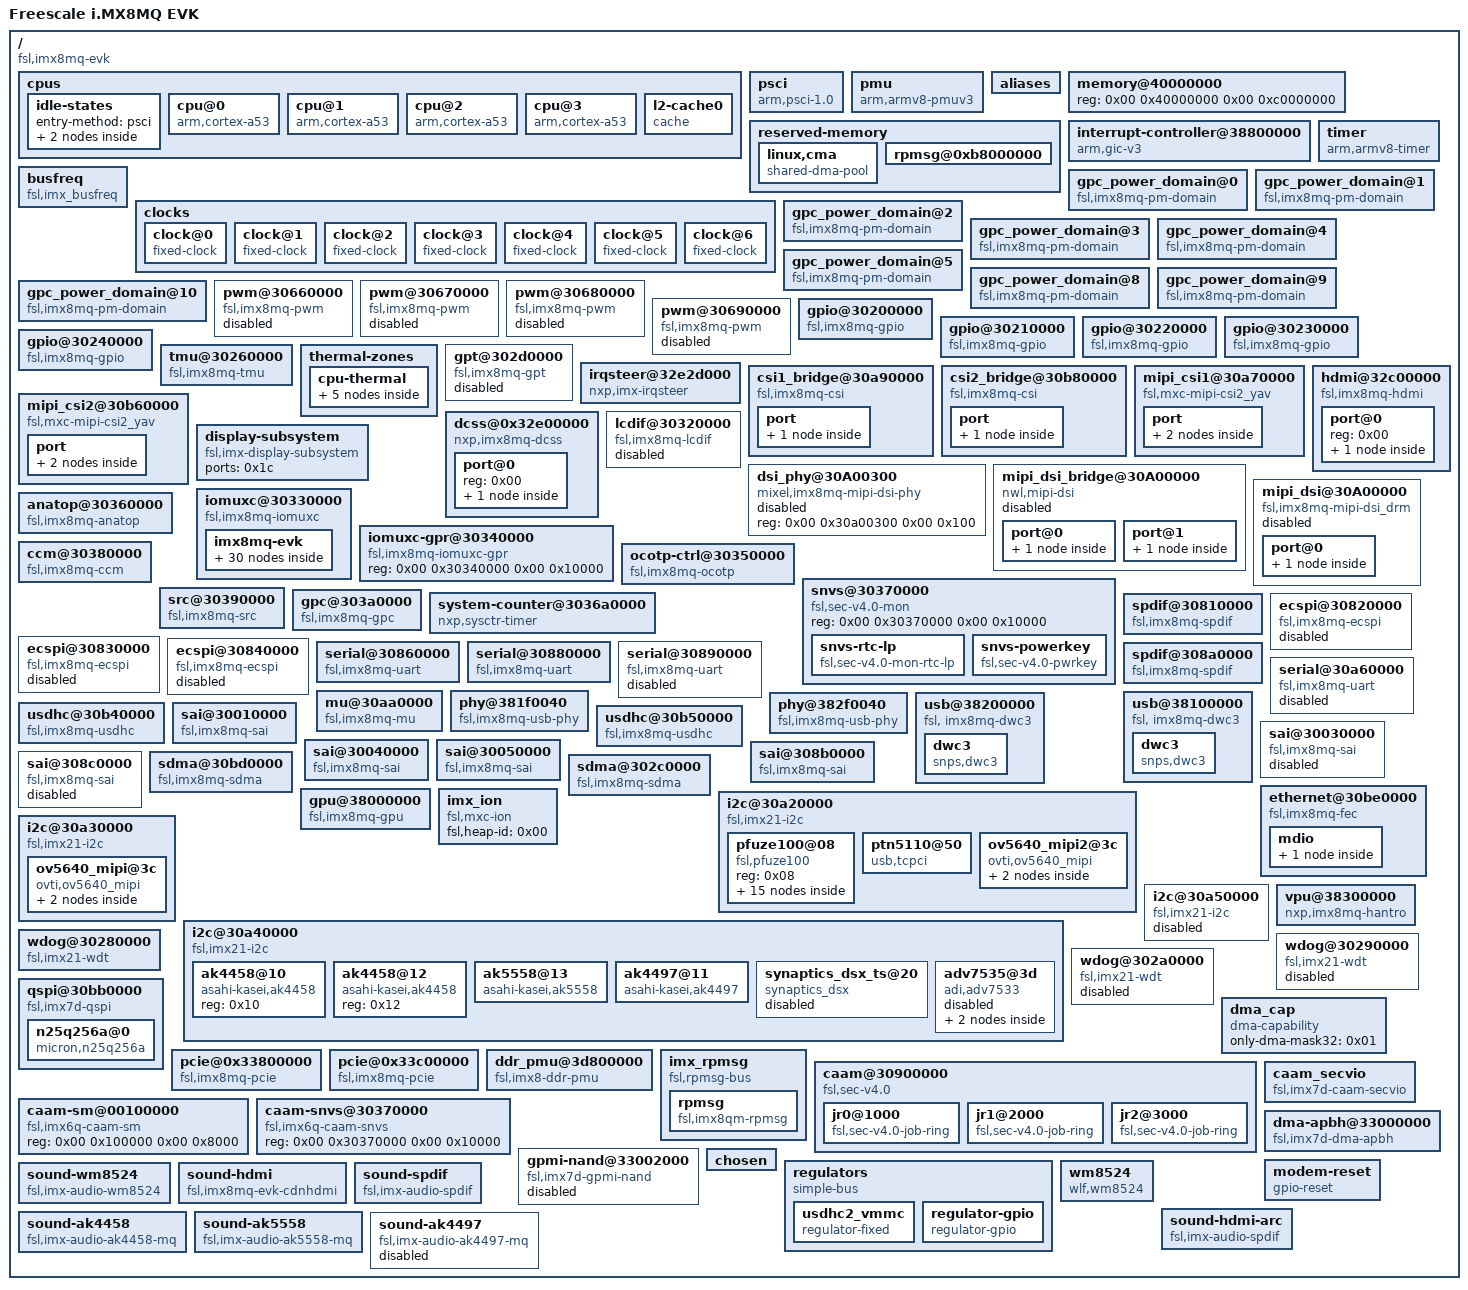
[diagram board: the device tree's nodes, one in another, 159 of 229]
/*
 * Copyright Linux Kernel Team
 *
 * SPDX-License-Identifier: GPL-2.0-only
 *
 * This file is derived from an intermediate build stage of the
 * Linux kernel. The licenses of all input files to this process
 * are compatible with GPL-2.0-only.
 */

/dts-v1/;

/ {
	compatible = "fsl,imx8mq-evk\0fsl,imx8mq";
	interrupt-parent = < 0x01 >;
	#address-cells = < 0x02 >;
	#size-cells = < 0x02 >;
	model = "Freescale i.MX8MQ EVK";

	cpus {
		#address-cells = < 0x02 >;
		#size-cells = < 0x00 >;

		idle-states {
			entry-method = "psci";

			cpu-sleep {
				compatible = "arm,idle-state";
				arm,psci-suspend-param = < 0x10033 >;
				entry-latency-us = < 0x3e8 >;
				exit-latency-us = < 0x2bc >;
				min-residency-us = < 0xa8c >;
				local-timer-stop;
				wakeup-latency-us = < 0x5dc >;
				linux,phandle = < 0x03 >;
				phandle = < 0x03 >;
			};

			cluster-sleep {
				compatible = "arm,idle-state";
				arm,psci-suspend-param = < 0x1000000 >;
				entry-latency-us = < 0x3e8 >;
				exit-latency-us = < 0x2bc >;
				min-residency-us = < 0xa8c >;
				wakeup-latency-us = < 0x5dc >;
			};
		};

		cpu@0 {
			device_type = "cpu";
			compatible = "arm,cortex-a53";
			reg = < 0x00 0x00 >;
			enable-method = "psci";
			next-level-cache = < 0x02 >;
			cpu-idle-states = < 0x03 >;
			operating-points = < 0x16e360 0xf4240 0x13d620 0xf4240 0xf4240 0xdbba0 0xc3500 0xdbba0 >;
			clocks = < 0x04 0x5a 0x04 0x58 0x04 0x0a 0x04 0x0c 0x04 0x4e >;
			clock-names = "a53\0arm_a53_src\0arm_pll\0arm_pll_out\0sys1_pll_800m";
			clock-latency = < 0xee6c >;
			#cooling-cells = < 0x02 >;
			dc-supply = < 0x05 >;
			linux,phandle = < 0x06 >;
			phandle = < 0x06 >;
		};

		cpu@1 {
			device_type = "cpu";
			compatible = "arm,cortex-a53";
			reg = < 0x00 0x01 >;
			enable-method = "psci";
			next-level-cache = < 0x02 >;
			cpu-idle-states = < 0x03 >;
			linux,phandle = < 0x07 >;
			phandle = < 0x07 >;
		};

		cpu@2 {
			device_type = "cpu";
			compatible = "arm,cortex-a53";
			reg = < 0x00 0x02 >;
			enable-method = "psci";
			next-level-cache = < 0x02 >;
			cpu-idle-states = < 0x03 >;
			linux,phandle = < 0x08 >;
			phandle = < 0x08 >;
		};

		cpu@3 {
			device_type = "cpu";
			compatible = "arm,cortex-a53";
			reg = < 0x00 0x03 >;
			enable-method = "psci";
			next-level-cache = < 0x02 >;
			cpu-idle-states = < 0x03 >;
			linux,phandle = < 0x09 >;
			phandle = < 0x09 >;
		};

		l2-cache0 {
			compatible = "cache";
			linux,phandle = < 0x02 >;
			phandle = < 0x02 >;
		};
	};

	psci {
		compatible = "arm,psci-1.0";
		method = "smc";
		cpu_suspend = < 0xc4000001 >;
		cpu_off = < 0xc4000002 >;
		cpu_on = < 0xc4000003 >;
	};

	pmu {
		compatible = "arm,armv8-pmuv3";
		interrupts = < 0x01 0x07 0x3f04 >;
		interrupt-affinity = < 0x06 0x07 0x08 0x09 >;
		interrupt-parent = < 0x0a >;
	};

	aliases {
		csi0 = "/mipi_csi1@30a70000";
		csi1 = "/mipi_csi2@30b60000";
		ethernet0 = "/ethernet@30be0000";
		serial0 = "/serial@30860000";
		serial1 = "/serial@30890000";
		serial2 = "/serial@30880000";
		serial3 = "/serial@30a60000";
		spi0 = "/ecspi@30820000";
		spi1 = "/ecspi@30830000";
		spi2 = "/ecspi@30840000";
		mmc0 = "/usdhc@30b40000";
		mmc1 = "/usdhc@30b50000";
		gpio0 = "/gpio@30200000";
		gpio1 = "/gpio@30210000";
		gpio2 = "/gpio@30220000";
		gpio3 = "/gpio@30230000";
		gpio4 = "/gpio@30240000";
		dsi_phy0 = "/dsi_phy@30A00300";
		mipi_dsi0 = "/mipi_dsi@30A00000";
	};

	memory@40000000 {
		device_type = "memory";
		reg = < 0x00 0x40000000 0x00 0xc0000000 >;
	};

	reserved-memory {
		#address-cells = < 0x02 >;
		#size-cells = < 0x02 >;
		ranges;

		linux,cma {
			compatible = "shared-dma-pool";
			reusable;
			size = < 0x00 0x3c000000 >;
			alloc-ranges = < 0x00 0x40000000 0x00 0x40000000 >;
			linux,cma-default;
		};

		rpmsg@0xb8000000 {
			no-map;
			reg = < 0x00 0xb8000000 0x00 0x400000 >;
			linux,phandle = < 0x58 >;
			phandle = < 0x58 >;
		};
	};

	interrupt-controller@38800000 {
		compatible = "arm,gic-v3";
		reg = < 0x00 0x38800000 0x00 0x10000 0x00 0x38880000 0x00 0xc0000 0x00 0x30340000 0x00 0x10000 >;
		#interrupt-cells = < 0x03 >;
		interrupt-controller;
		interrupts = < 0x01 0x09 0x04 >;
		interrupt-parent = < 0x0a >;
		linux,phandle = < 0x0a >;
		phandle = < 0x0a >;
	};

	timer {
		compatible = "arm,armv8-timer";
		interrupts = < 0x01 0x0d 0x3f08 0x01 0x0e 0x3f08 0x01 0x0b 0x3f08 0x01 0x0a 0x3f08 >;
		clock-frequency = < 0x7f2815 >;
		interrupt-parent = < 0x0a >;
		arm,no-tick-in-suspend;
	};

	busfreq {
		compatible = "fsl,imx_busfreq";
		clocks = < 0x04 0xf8 0x04 0x75 0x04 0x76 0x04 0x76 0x04 0x112 0x04 0x111 0x04 0x46 0x04 0x4d 0x04 0x48 0x04 0x4e 0x04 0x71 0x04 0x67 0x04 0x73 0x04 0x02 0x04 0x55 0x04 0x49 >;
		clock-names = "dram_pll\0dram_alt_src\0dram_apb_src\0dram_apb_pre_div\0dram_core\0dram_alt_root\0sys1_pll_40m\0sys1_pll_400m\0sys1_pll_100m\0sys1_pll_800m\0noc_div\0main_axi_src\0ahb_div\0osc_25m\0sys2_pll_333m\0sys1_pll_133m";
		interrupts = < 0x00 0x66 0x04 0x00 0x6d 0x04 0x00 0x6e 0x04 0x00 0x6f 0x04 >;
		interrupt-name = "irq_busfreq_0\0irq_busfreq_1\0irq_busfreq_2\0irq_busfreq_3";
	};

	clocks {
		#address-cells = < 0x01 >;
		#size-cells = < 0x00 >;

		clock@0 {
			compatible = "fixed-clock";
			reg = < 0x00 >;
			#clock-cells = < 0x00 >;
			clock-frequency = < 0x8000 >;
			clock-output-names = "ckil";
			linux,phandle = < 0x24 >;
			phandle = < 0x24 >;
		};

		clock@1 {
			compatible = "fixed-clock";
			reg = < 0x01 >;
			#clock-cells = < 0x00 >;
			clock-frequency = < 0x17d7840 >;
			clock-output-names = "osc_25m";
			linux,phandle = < 0x25 >;
			phandle = < 0x25 >;
		};

		clock@2 {
			compatible = "fixed-clock";
			reg = < 0x02 >;
			#clock-cells = < 0x00 >;
			clock-frequency = < 0x19bfcc0 >;
			clock-output-names = "osc_27m";
			linux,phandle = < 0x26 >;
			phandle = < 0x26 >;
		};

		clock@3 {
			compatible = "fixed-clock";
			reg = < 0x03 >;
			#clock-cells = < 0x00 >;
			clock-frequency = < 0x7ed6b40 >;
			clock-output-names = "clk_ext1";
			linux,phandle = < 0x27 >;
			phandle = < 0x27 >;
		};

		clock@4 {
			compatible = "fixed-clock";
			reg = < 0x04 >;
			#clock-cells = < 0x00 >;
			clock-frequency = < 0x7ed6b40 >;
			clock-output-names = "clk_ext2";
			linux,phandle = < 0x28 >;
			phandle = < 0x28 >;
		};

		clock@5 {
			compatible = "fixed-clock";
			reg = < 0x05 >;
			#clock-cells = < 0x00 >;
			clock-frequency = < 0x7ed6b40 >;
			clock-output-names = "clk_ext3";
			linux,phandle = < 0x29 >;
			phandle = < 0x29 >;
		};

		clock@6 {
			compatible = "fixed-clock";
			reg = < 0x06 >;
			#clock-cells = < 0x00 >;
			clock-frequency = < 0x7ed6b40 >;
			clock-output-names = "clk_ext4";
			linux,phandle = < 0x2a >;
			phandle = < 0x2a >;
		};
	};

	gpc_power_domain@0 {
		compatible = "fsl,imx8mq-pm-domain";
		#power-domain-cells = < 0x00 >;
		domain-id = < 0x00 >;
		domain-name = "MIPI_PD";
		linux,phandle = < 0x20 >;
		phandle = < 0x20 >;
	};

	gpc_power_domain@1 {
		compatible = "fsl,imx8mq-pm-domain";
		#power-domain-cells = < 0x00 >;
		domain-id = < 0x01 >;
		domain-name = "PCIE0_PD";
		linux,phandle = < 0x59 >;
		phandle = < 0x59 >;
	};

	gpc_power_domain@2 {
		compatible = "fsl,imx8mq-pm-domain";
		#power-domain-cells = < 0x00 >;
		domain-id = < 0x02 >;
		domain-name = "USB_OTG1_PD";
		linux,phandle = < 0x31 >;
		phandle = < 0x31 >;
	};

	gpc_power_domain@3 {
		compatible = "fsl,imx8mq-pm-domain";
		#power-domain-cells = < 0x00 >;
		domain-id = < 0x03 >;
		domain-name = "USB_OTG2_PD";
		linux,phandle = < 0x34 >;
		phandle = < 0x34 >;
	};

	gpc_power_domain@4 {
		compatible = "fsl,imx8mq-pm-domain";
		#power-domain-cells = < 0x00 >;
		domain-id = < 0x04 >;
		domain-name = "GPU_PD";
		clocks = < 0x04 0x6f 0x04 0x66 0x04 0xe5 0x04 0x70 >;
		power-supply = < 0x0b >;
		linux,phandle = < 0x46 >;
		phandle = < 0x46 >;
	};

	gpc_power_domain@5 {
		compatible = "fsl,imx8mq-pm-domain";
		#power-domain-cells = < 0x00 >;
		domain-id = < 0x05 >;
		domain-name = "VPU_PD";
		clocks = < 0x04 0xf3 0x04 0xf4 0x04 0xed >;
		power-supply = < 0x0c >;
		linux,phandle = < 0x55 >;
		phandle = < 0x55 >;
	};

	gpc_power_domain@8 {
		compatible = "fsl,imx8mq-pm-domain";
		#power-domain-cells = < 0x00 >;
		domain-id = < 0x08 >;
		domain-name = "MIPI_CSI1_PD";
		linux,phandle = < 0x11 >;
		phandle = < 0x11 >;
	};

	gpc_power_domain@9 {
		compatible = "fsl,imx8mq-pm-domain";
		#power-domain-cells = < 0x00 >;
		domain-id = < 0x09 >;
		domain-name = "MIPI_CSI2_PD";
		linux,phandle = < 0x16 >;
		phandle = < 0x16 >;
	};

	gpc_power_domain@10 {
		compatible = "fsl,imx8mq-pm-domain";
		#power-domain-cells = < 0x00 >;
		domain-id = < 0x0a >;
		domain-name = "PCIE1_PD";
		linux,phandle = < 0x5b >;
		phandle = < 0x5b >;
	};

	pwm@30660000 {
		compatible = "fsl,imx8mq-pwm\0fsl,imx27-pwm";
		reg = < 0x00 0x30660000 0x00 0x10000 >;
		interrupts = < 0x00 0x51 0x04 >;
		clocks = < 0x04 0xcd 0x04 0xcd >;
		clock-names = "ipg\0per";
		#pwm-cells = < 0x02 >;
		status = "disabled";
	};

	pwm@30670000 {
		compatible = "fsl,imx8mq-pwm\0fsl,imx27-pwm";
		reg = < 0x00 0x30670000 0x00 0x10000 >;
		interrupts = < 0x00 0x52 0x04 >;
		clocks = < 0x04 0xce 0x04 0xce >;
		clock-names = "ipg\0per";
		#pwm-cells = < 0x02 >;
		status = "disabled";
	};

	pwm@30680000 {
		compatible = "fsl,imx8mq-pwm\0fsl,imx27-pwm";
		reg = < 0x00 0x30680000 0x00 0x10000 >;
		interrupts = < 0x00 0x53 0x04 >;
		clocks = < 0x04 0xcf 0x04 0xcf >;
		clock-names = "ipg\0per";
		#pwm-cells = < 0x02 >;
		status = "disabled";
	};

	pwm@30690000 {
		compatible = "fsl,imx8mq-pwm\0fsl,imx27-pwm";
		reg = < 0x00 0x30690000 0x00 0x10000 >;
		interrupts = < 0x00 0x54 0x04 >;
		clocks = < 0x04 0xd0 0x04 0xd0 >;
		clock-names = "ipg\0per";
		#pwm-cells = < 0x02 >;
		status = "disabled";
	};

	gpio@30200000 {
		compatible = "fsl,imx8mq-gpio\0fsl,imx35-gpio";
		reg = < 0x00 0x30200000 0x00 0x10000 >;
		interrupts = < 0x00 0x40 0x04 0x00 0x41 0x04 >;
		gpio-controller;
		#gpio-cells = < 0x02 >;
		interrupt-controller;
		#interrupt-cells = < 0x02 >;
		linux,phandle = < 0x4c >;
		phandle = < 0x4c >;
	};

	gpio@30210000 {
		compatible = "fsl,imx8mq-gpio\0fsl,imx35-gpio";
		reg = < 0x00 0x30210000 0x00 0x10000 >;
		interrupts = < 0x00 0x42 0x04 0x00 0x43 0x04 >;
		gpio-controller;
		#gpio-cells = < 0x02 >;
		interrupt-controller;
		#interrupt-cells = < 0x02 >;
		linux,phandle = < 0x3c >;
		phandle = < 0x3c >;
	};

	gpio@30220000 {
		compatible = "fsl,imx8mq-gpio\0fsl,imx35-gpio";
		reg = < 0x00 0x30220000 0x00 0x10000 >;
		interrupts = < 0x00 0x44 0x04 0x00 0x45 0x04 >;
		gpio-controller;
		#gpio-cells = < 0x02 >;
		interrupt-controller;
		#interrupt-cells = < 0x02 >;
		linux,phandle = < 0x49 >;
		phandle = < 0x49 >;
	};

	gpio@30230000 {
		compatible = "fsl,imx8mq-gpio\0fsl,imx35-gpio";
		reg = < 0x00 0x30230000 0x00 0x10000 >;
		interrupts = < 0x00 0x46 0x04 0x00 0x47 0x04 >;
		gpio-controller;
		#gpio-cells = < 0x02 >;
		interrupt-controller;
		#interrupt-cells = < 0x02 >;
	};

	gpio@30240000 {
		compatible = "fsl,imx8mq-gpio\0fsl,imx35-gpio";
		reg = < 0x00 0x30240000 0x00 0x10000 >;
		interrupts = < 0x00 0x48 0x04 0x00 0x49 0x04 >;
		gpio-controller;
		#gpio-cells = < 0x02 >;
		interrupt-controller;
		#interrupt-cells = < 0x02 >;
		linux,phandle = < 0x53 >;
		phandle = < 0x53 >;
	};

	tmu@30260000 {
		compatible = "fsl,imx8mq-tmu";
		reg = < 0x00 0x30260000 0x00 0x10000 >;
		interrupt = < 0x00 0x31 0x04 >;
		little-endian;
		fsl,tmu-range = < 0xb0000 0xa0026 0x80048 0x70061 >;
		fsl,tmu-calibration = < 0x00 0x23 0x01 0x29 0x02 0x2f 0x03 0x35 0x04 0x3d 0x05 0x43 0x06 0x4b 0x07 0x51 0x08 0x57 0x09 0x5f 0x0a 0x67 0x0b 0x6f 0x10000 0x1b 0x10001 0x23 0x10002 0x2b 0x10003 0x33 0x10004 0x3b 0x10005 0x43 0x10006 0x4b 0x10007 0x55 0x10008 0x5d 0x10009 0x67 0x1000a 0x70 0x20000 0x17 0x20001 0x23 0x20002 0x2d 0x20003 0x37 0x20004 0x41 0x20005 0x4b 0x20006 0x57 0x20007 0x63 0x20008 0x6f 0x30000 0x15 0x30001 0x21 0x30002 0x2d 0x30003 0x39 0x30004 0x45 0x30005 0x53 0x30006 0x5f 0x30007 0x71 >;
		#thermal-sensor-cells = < 0x00 >;
		linux,phandle = < 0x0d >;
		phandle = < 0x0d >;
	};

	thermal-zones {

		cpu-thermal {
			polling-delay-passive = < 0xfa >;
			polling-delay = < 0x7d0 >;
			thermal-sensors = < 0x0d >;

			trips {

				trip0 {
					temperature = < 0x14c08 >;
					hysteresis = < 0x7d0 >;
					type = "passive";
					linux,phandle = < 0x0e >;
					phandle = < 0x0e >;
				};

				trip1 {
					temperature = < 0x17318 >;
					hysteresis = < 0x7d0 >;
					type = "critical";
				};
			};

			cooling-maps {

				map0 {
					trip = < 0x0e >;
					cooling-device = < 0x06 0xffffffff 0xffffffff >;
				};
			};
		};
	};

	gpt@302d0000 {
		compatible = "fsl,imx8mq-gpt\0fsl,imx7d-gpt";
		reg = < 0x00 0x302d0000 0x00 0x10000 >;
		interrupts = < 0x00 0x37 0x04 >;
		clocks = < 0x04 0xc5 0x04 0xc5 0x04 0xf9 >;
		clock-names = "ipg\0per\0osc_per";
		status = "disabled";
	};

	irqsteer@32e2d000 {
		compatible = "nxp,imx-irqsteer";
		reg = < 0x00 0x32e2d000 0x00 0x1000 >;
		interrupts = < 0x00 0x12 0x04 >;
		interrupt-controller;
		#interrupt-cells = < 0x02 >;
		nxp,irqsteer_chans = < 0x02 >;
		nxp,endian = < 0x01 >;
		clocks = < 0x04 0x10e >;
		clock-names = "ipg";
		linux,phandle = < 0x19 >;
		phandle = < 0x19 >;
	};

	csi1_bridge@30a90000 {
		compatible = "fsl,imx8mq-csi\0fsl,imx6s-csi";
		reg = < 0x00 0x30a90000 0x00 0x10000 >;
		interrupts = < 0x00 0x2a 0x04 >;
		clocks = < 0x04 0x00 0x04 0xee 0x04 0x00 >;
		clock-names = "disp-axi\0csi_mclk\0disp_dcic";
		status = "okay";
		fsl,mipi-mode;
		fsl,two-8bit-sensor-mode;

		port {

			endpoint {
				remote-endpoint = < 0x0f >;
				linux,phandle = < 0x15 >;
				phandle = < 0x15 >;
			};
		};
	};

	csi2_bridge@30b80000 {
		compatible = "fsl,imx8mq-csi\0fsl,imx6s-csi";
		reg = < 0x00 0x30b80000 0x00 0x10000 >;
		interrupts = < 0x00 0x2b 0x04 >;
		clocks = < 0x04 0x00 0x04 0xef 0x04 0x00 >;
		clock-names = "disp-axi\0csi_mclk\0disp_dcic";
		status = "okay";
		fsl,mipi-mode;
		fsl,two-8bit-sensor-mode;

		port {

			endpoint {
				remote-endpoint = < 0x10 >;
				linux,phandle = < 0x18 >;
				phandle = < 0x18 >;
			};
		};
	};

	mipi_csi1@30a70000 {
		compatible = "fsl,mxc-mipi-csi2_yav";
		reg = < 0x00 0x30a70000 0x00 0x1000 >;
		interrupts = < 0x00 0x2c 0x04 >;
		clocks = < 0x04 0x00 0x04 0xa7 0x04 0xa9 0x04 0xa8 >;
		clock-names = "clk_apb\0clk_core\0clk_esc\0clk_pxl";
		assigned-clocks = < 0x04 0xa7 0x04 0xa8 0x04 0xa9 >;
		assigned-clock-rates = < 0x7ed6b40 0x5f5e100 0x3ef1480 >;
		power-domains = < 0x11 >;
		csis-phy-reset = < 0x12 0x4c 0x07 >;
		phy-gpr = < 0x13 0x88 >;
		status = "okay";
		#address-cells = < 0x01 >;
		#size-cells = < 0x00 >;

		port {

			endpoint1 {
				remote-endpoint = < 0x14 >;
				data-lanes = < 0x01 0x02 >;
				linux,phandle = < 0x50 >;
				phandle = < 0x50 >;
			};

			endpoint2 {
				remote-endpoint = < 0x15 >;
				linux,phandle = < 0x0f >;
				phandle = < 0x0f >;
			};
		};
	};

	mipi_csi2@30b60000 {
		compatible = "fsl,mxc-mipi-csi2_yav";
		reg = < 0x00 0x30b60000 0x00 0x1000 >;
		interrupts = < 0x00 0x2d 0x04 >;
		clocks = < 0x04 0x00 0x04 0xaa 0x04 0xac 0x04 0xab >;
		clock-names = "clk_apb\0clk_core\0clk_esc\0clk_pxl";
		assigned-clocks = < 0x04 0xaa 0x04 0xab 0x04 0xac >;
		assigned-clock-rates = < 0x7ed6b40 0x5f5e100 0x3ef1480 >;
		power-domains = < 0x16 >;
		csis-phy-reset = < 0x12 0x50 0x07 >;
		phy-gpr = < 0x13 0xa4 >;
		status = "okay";
		#address-cells = < 0x01 >;
		#size-cells = < 0x00 >;

		port {

			endpoint1 {
				remote-endpoint = < 0x17 >;
				data-lanes = < 0x01 0x02 >;
				linux,phandle = < 0x4d >;
				phandle = < 0x4d >;
			};

			endpoint2 {
				remote-endpoint = < 0x18 >;
				linux,phandle = < 0x10 >;
				phandle = < 0x10 >;
			};
		};
	};

	dcss@0x32e00000 {
		#address-cells = < 0x01 >;
		#size-cells = < 0x00 >;
		compatible = "nxp,imx8mq-dcss";
		reg = < 0x00 0x32e00000 0x00 0x30000 >;
		interrupts = < 0x03 0x04 0x04 0x04 0x05 0x04 0x06 0x04 0x08 0x04 0x09 0x01 0x10 0x04 0x11 0x04 >;
		interrupt-names = "dpr_dc_ch0\0dpr_dc_ch1\0dpr_dc_ch2\0ctx_ld\0ctxld_kick\0dtg_prg1\0dtrc_ch1\0dtrc_ch2";
		interrupt-parent = < 0x19 >;
		clocks = < 0x04 0x10e 0x04 0x10d 0x04 0x10f 0x04 0x00 0x04 0x00 0x04 0x79 >;
		clock-names = "apb\0axi\0rtrm\0pix_div\0pix_out\0dtrc";
		assigned-clocks = < 0x04 0x7e 0x04 0x6b 0x04 0x6d >;
		assigned-clock-parents = < 0x04 0x25 0x04 0x4e 0x04 0x4e >;
		assigned-clock-rates = < 0x2367b880 0x2faf0800 0x17d78400 >;
		status = "okay";
		disp-dev = "hdmi_disp";

		port@0 {
			reg = < 0x00 >;
			linux,phandle = < 0x1c >;
			phandle = < 0x1c >;

			hdmi-endpoint {
				remote-endpoint = < 0x1a >;
				linux,phandle = < 0x1b >;
				phandle = < 0x1b >;
			};
		};
	};

	hdmi@32c00000 {
		#address-cells = < 0x01 >;
		#size-cells = < 0x00 >;
		compatible = "fsl,imx8mq-hdmi";
		reg = < 0x00 0x32c00000 0x00 0x100000 0x00 0x32e40000 0x00 0x40000 0x00 0x32e2f000 0x00 0x10 >;
		interrupts = < 0x00 0x10 0x04 0x00 0x19 0x04 >;
		interrupt-names = "plug_in\0plug_out";
		fsl,cec;
		status = "okay";

		port@0 {
			reg = < 0x00 >;

			endpoint {
				remote-endpoint = < 0x1b >;
				linux,phandle = < 0x1a >;
				phandle = < 0x1a >;
			};
		};
	};

	lcdif@30320000 {
		compatible = "fsl,imx8mq-lcdif\0fsl,imx28-lcdif";
		reg = < 0x00 0x30320000 0x00 0x10000 >;
		clocks = < 0x04 0x7f >;
		clock-names = "pix";
		assigned-clocks = < 0x04 0x7f >;
		assigned-clock-parents = < 0x04 0x25 >;
		assigned-clock-rate = < 0x2367b880 >;
		interrupts = < 0x00 0x05 0x04 >;
		status = "disabled";
	};

	display-subsystem {
		compatible = "fsl,imx-display-subsystem";
		ports = < 0x1c >;
	};

	dsi_phy@30A00300 {
		#address-cells = < 0x01 >;
		#size-cells = < 0x00 >;
		compatible = "mixel,imx8mq-mipi-dsi-phy";
		reg = < 0x00 0x30a00300 0x00 0x100 >;
		#phy-cells = < 0x00 >;
		status = "disabled";
		linux,phandle = < 0x1d >;
		phandle = < 0x1d >;
	};

	mipi_dsi_bridge@30A00000 {
		#address-cells = < 0x01 >;
		#size-cells = < 0x00 >;
		compatible = "nwl,mipi-dsi";
		reg = < 0x00 0x30a00000 0x00 0x400 >;
		interrupts = < 0x00 0x22 0x04 >;
		clocks = < 0x04 0xa4 0x04 0x102 0x04 0x103 >;
		clock-names = "phy_ref\0rx_esc\0tx_esc";
		assigned-clocks = < 0x04 0x102 >;
		assigned-clock-parents = < 0x04 0x47 >;
		assigned-clock-rates = < 0x4c4b400 >;
		phys = < 0x1d >;
		phy-names = "dphy";
		no_clk_reset;
		status = "disabled";

		port@0 {

			endpoint {
				remote-endpoint = < 0x1e >;
				linux,phandle = < 0x21 >;
				phandle = < 0x21 >;
			};
		};

		port@1 {

			endpoint {
				remote-endpoint = < 0x1f >;
				linux,phandle = < 0x54 >;
				phandle = < 0x54 >;
			};
		};
	};

	mipi_dsi@30A00000 {
		compatible = "fsl,imx8mq-mipi-dsi_drm";
		clocks = < 0x04 0xa3 0x04 0xa4 >;
		clock-names = "core\0phy_ref";
		assigned-clocks = < 0x04 0xa4 0x04 0xa3 >;
		assigned-clock-parents = < 0x04 0x25 0x04 0x4c >;
		assigned-clock-rates = < 0x2367b880 0xfdad680 >;
		power-domains = < 0x20 >;
		src = < 0x12 >;
		mux-sel = < 0x13 >;
		phys = < 0x1d >;
		phy-names = "dphy";
		no_clk_reset;
		status = "disabled";

		port@0 {

			endpoint {
				remote-endpoint = < 0x21 >;
				linux,phandle = < 0x1e >;
				phandle = < 0x1e >;
			};
		};
	};

	iomuxc@30330000 {
		compatible = "fsl,imx8mq-iomuxc";
		reg = < 0x00 0x30330000 0x00 0x10000 >;
		pinctrl-names = "default";
		pinctrl-0 = < 0x22 >;

		imx8mq-evk {

			hoggrp {
				fsl,pins = < 0x134 0x39c 0x00 0x05 0x00 0x19 0x138 0x3a0 0x00 0x05 0x00 0x19 0x13c 0x3a4 0x00 0x05 0x00 0x19 >;
				linux,phandle = < 0x22 >;
				phandle = < 0x22 >;
			};

			csi1_pwn_grp {
				fsl,pins = < 0x34 0x29c 0x00 0x00 0x00 0x19 >;
				linux,phandle = < 0x4f >;
				phandle = < 0x4f >;
			};

			csi2_pwn_grp {
				fsl,pins = < 0x3c 0x2a4 0x00 0x00 0x00 0x19 >;
				linux,phandle = < 0x4a >;
				phandle = < 0x4a >;
			};

			csi_rst_grp {
				fsl,pins = < 0x40 0x2a8 0x00 0x00 0x00 0x19 0x64 0x2cc 0x00 0x06 0x00 0x59 >;
				linux,phandle = < 0x4b >;
				phandle = < 0x4b >;
			};

			fec1grp {
				fsl,pins = < 0x68 0x2d0 0x00 0x00 0x00 0x03 0x6c 0x2d4 0x4c0 0x00 0x01 0x23 0x70 0x2d8 0x00 0x00 0x00 0x1f 0x74 0x2dc 0x00 0x00 0x00 0x1f 0x78 0x2e0 0x00 0x00 0x00 0x1f 0x7c 0x2e4 0x00 0x00 0x00 0x1f 0x9c 0x304 0x00 0x00 0x00 0x91 0x98 0x300 0x00 0x00 0x00 0x91 0x94 0x2fc 0x00 0x00 0x00 0x91 0x90 0x2f8 0x00 0x00 0x00 0x91 0x84 0x2ec 0x00 0x00 0x00 0x1f 0x8c 0x2f4 0x00 0x00 0x00 0x91 0x88 0x2f0 0x00 0x00 0x00 0x91 0x80 0x2e8 0x00 0x00 0x00 0x1f 0x4c 0x2b4 0x00 0x00 0x00 0x19 >;
				linux,phandle = < 0x44 >;
				phandle = < 0x44 >;
			};

			i2c1grp {
				fsl,pins = < 0x214 0x47c 0x00 0x00 0x00 0x4000007f 0x218 0x480 0x00 0x00 0x00 0x4000007f >;
				linux,phandle = < 0x47 >;
				phandle = < 0x47 >;
			};

			i2c2grp {
				fsl,pins = < 0x21c 0x484 0x00 0x00 0x00 0x40000067 0x220 0x488 0x00 0x00 0x00 0x40000067 >;
				linux,phandle = < 0x4e >;
				phandle = < 0x4e >;
			};

			i2c3grp {
				fsl,pins = < 0x224 0x48c 0x00 0x00 0x00 0x40000067 0x228 0x490 0x00 0x00 0x00 0x40000067 >;
				linux,phandle = < 0x51 >;
				phandle = < 0x51 >;
			};

			pcie0grp {
				fsl,pins = < 0x22c 0x494 0x524 0x12 0x00 0x76 0x250 0x4b8 0x00 0x05 0x00 0x16 0x24c 0x4b4 0x00 0x05 0x00 0x16 >;
				linux,phandle = < 0x5a >;
				phandle = < 0x5a >;
			};

			pcie1grp {
				fsl,pins = < 0x230 0x498 0x528 0x12 0x00 0x76 0x204 0x46c 0x00 0x05 0x00 0x16 0x20c 0x474 0x00 0x05 0x00 0x16 >;
				linux,phandle = < 0x5c >;
				phandle = < 0x5c >;
			};

			dvfsgrp {
				fsl,pins = < 0x5c 0x2c4 0x00 0x00 0x00 0x16 >;
				linux,phandle = < 0x5e >;
				phandle = < 0x5e >;
			};

			typecgrp {
				fsl,pins = < 0x130 0x398 0x00 0x05 0x00 0x16 0x100 0x368 0x00 0x05 0x00 0x17059 >;
				linux,phandle = < 0x48 >;
				phandle = < 0x48 >;
			};

			qspigrp {
				fsl,pins = < 0xf4 0x35c 0x00 0x01 0x00 0x82 0xf8 0x360 0x00 0x01 0x00 0x82 0x10c 0x374 0x00 0x01 0x00 0x82 0x110 0x378 0x00 0x01 0x00 0x82 0x114 0x37c 0x00 0x01 0x00 0x82 0x118 0x380 0x00 0x01 0x00 0x82 >;
				linux,phandle = < 0x57 >;
				phandle = < 0x57 >;
			};

			uart1grp {
				fsl,pins = < 0x234 0x49c 0x4f4 0x00 0x00 0x49 0x238 0x4a0 0x00 0x00 0x00 0x49 >;
				linux,phandle = < 0x2d >;
				phandle = < 0x2d >;
			};

			uart3grp {
				fsl,pins = < 0x248 0x4b0 0x00 0x00 0x00 0x49 0x244 0x4ac 0x504 0x00 0x02 0x49 0x1fc 0x464 0x00 0x01 0x00 0x49 0x200 0x468 0x500 0x01 0x01 0x49 0x108 0x370 0x00 0x05 0x00 0x19 >;
				linux,phandle = < 0x2e >;
				phandle = < 0x2e >;
			};

			usdhc1grp {
				fsl,pins = < 0xa0 0x308 0x00 0x00 0x00 0x83 0xa4 0x30c 0x00 0x00 0x00 0xc3 0xa8 0x310 0x00 0x00 0x00 0xc3 0xac 0x314 0x00 0x00 0x00 0xc3 0xb0 0x318 0x00 0x00 0x00 0xc3 0xb4 0x31c 0x00 0x00 0x00 0xc3 0xb8 0x320 0x00 0x00 0x00 0xc3 0xbc 0x324 0x00 0x00 0x00 0xc3 0xc0 0x328 0x00 0x00 0x00 0xc3 0xc4 0x32c 0x00 0x00 0x00 0xc3 0xcc 0x334 0x00 0x00 0x00 0x83 0xc8 0x330 0x00 0x00 0x00 0xc1 >;
				linux,phandle = < 0x35 >;
				phandle = < 0x35 >;
			};

			usdhc1grp100mhz {
				fsl,pins = < 0xa0 0x308 0x00 0x00 0x00 0x8d 0xa4 0x30c 0x00 0x00 0x00 0xcd 0xa8 0x310 0x00 0x00 0x00 0xcd 0xac 0x314 0x00 0x00 0x00 0xcd 0xb0 0x318 0x00 0x00 0x00 0xcd 0xb4 0x31c 0x00 0x00 0x00 0xcd 0xb8 0x320 0x00 0x00 0x00 0xcd 0xbc 0x324 0x00 0x00 0x00 0xcd 0xc0 0x328 0x00 0x00 0x00 0xcd 0xc4 0x32c 0x00 0x00 0x00 0xcd 0xcc 0x334 0x00 0x00 0x00 0x8d 0xc8 0x330 0x00 0x00 0x00 0xc1 >;
				linux,phandle = < 0x36 >;
				phandle = < 0x36 >;
			};

			usdhc1grp200mhz {
				fsl,pins = < 0xa0 0x308 0x00 0x00 0x00 0x9f 0xa4 0x30c 0x00 0x00 0x00 0xdf 0xa8 0x310 0x00 0x00 0x00 0xdf 0xac 0x314 0x00 0x00 0x00 0xdf 0xb0 0x318 0x00 0x00 0x00 0xdf 0xb4 0x31c 0x00 0x00 0x00 0xdf 0xb8 0x320 0x00 0x00 0x00 0xdf 0xbc 0x324 0x00 0x00 0x00 0xdf 0xc0 0x328 0x00 0x00 0x00 0xdf 0xc4 0x32c 0x00 0x00 0x00 0xdf 0xcc 0x334 0x00 0x00 0x00 0x9f 0xc8 0x330 0x00 0x00 0x00 0xc1 >;
				linux,phandle = < 0x37 >;
				phandle = < 0x37 >;
			};

			usdhc2grpgpio {
				fsl,pins = < 0xd0 0x338 0x00 0x05 0x00 0x41 0xec 0x354 0x00 0x05 0x00 0x41 >;
				linux,phandle = < 0x39 >;
				phandle = < 0x39 >;
			};

			usdhc2grp {
				fsl,pins = < 0xd4 0x33c 0x00 0x00 0x00 0x83 0xd8 0x340 0x00 0x00 0x00 0xc3 0xdc 0x344 0x00 0x00 0x00 0xc3 0xe0 0x348 0x00 0x00 0x00 0xc3 0xe4 0x34c 0x00 0x00 0x00 0xc3 0xe8 0x350 0x00 0x00 0x00 0xc3 0x38 0x2a0 0x00 0x01 0x00 0xc1 >;
				linux,phandle = < 0x38 >;
				phandle = < 0x38 >;
			};

			usdhc2grp100mhz {
				fsl,pins = < 0xd4 0x33c 0x00 0x00 0x00 0x8d 0xd8 0x340 0x00 0x00 0x00 0xcd 0xdc 0x344 0x00 0x00 0x00 0xcd 0xe0 0x348 0x00 0x00 0x00 0xcd 0xe4 0x34c 0x00 0x00 0x00 0xcd 0xe8 0x350 0x00 0x00 0x00 0xcd 0x38 0x2a0 0x00 0x01 0x00 0xc1 >;
				linux,phandle = < 0x3a >;
				phandle = < 0x3a >;
			};

			usdhc2grp200mhz {
				fsl,pins = < 0xd4 0x33c 0x00 0x00 0x00 0x9f 0xd8 0x340 0x00 0x00 0x00 0xdf 0xdc 0x344 0x00 0x00 0x00 0xdf 0xe0 0x348 0x00 0x00 0x00 0xdf 0xe4 0x34c 0x00 0x00 0x00 0xdf 0xe8 0x350 0x00 0x00 0x00 0xdf 0x38 0x2a0 0x00 0x01 0x00 0xc1 >;
				linux,phandle = < 0x3b >;
				phandle = < 0x3b >;
			};

			sai1grp_pcm {
				fsl,pins = < 0x1ac 0x414 0x00 0x00 0x00 0xd6 0x184 0x3ec 0x4cc 0x00 0x03 0xd6 0x180 0x3e8 0x4cc 0x02 0x04 0xd6 0x188 0x3f0 0x4c8 0x00 0x01 0xd6 0x18c 0x3f4 0x00 0x00 0x00 0xd6 0x190 0x3f8 0x00 0x00 0x00 0xd6 0x194 0x3fc 0x00 0x00 0x00 0xd6 0x198 0x400 0x00 0x00 0x00 0xd6 0x19c 0x404 0x00 0x00 0x00 0xd6 0x1a0 0x408 0x00 0x00 0x00 0xd6 0x1a4 0x40c 0x00 0x00 0x00 0xd6 0x1a8 0x410 0x00 0x00 0x00 0xd6 >;
				linux,phandle = < 0x3f >;
				phandle = < 0x3f >;
			};

			sai1grp_pcm_b2m {
				fsl,pins = < 0x1ac 0x414 0x4c8 0x02 0x02 0xd6 0x184 0x3ec 0x4cc 0x00 0x03 0xd6 0x180 0x3e8 0x4cc 0x02 0x04 0xd6 0x188 0x3f0 0x4c8 0x00 0x01 0xd6 0x18c 0x3f4 0x00 0x00 0x00 0xd6 0x190 0x3f8 0x00 0x00 0x00 0xd6 0x194 0x3fc 0x00 0x00 0x00 0xd6 0x198 0x400 0x00 0x00 0x00 0xd6 0x19c 0x404 0x00 0x00 0x00 0xd6 0x1a0 0x408 0x00 0x00 0x00 0xd6 0x1a4 0x40c 0x00 0x00 0x00 0xd6 0x1a8 0x410 0x00 0x00 0x00 0xd6 >;
				linux,phandle = < 0x40 >;
				phandle = < 0x40 >;
			};

			sai1grp_dsd {
				fsl,pins = < 0x1ac 0x414 0x00 0x00 0x00 0xd6 0x184 0x3ec 0x4cc 0x00 0x03 0xd6 0x180 0x3e8 0x00 0x03 0x00 0xd6 0x188 0x3f0 0x4c8 0x00 0x01 0xd6 0x18c 0x3f4 0x00 0x00 0x00 0xd6 0x190 0x3f8 0x00 0x00 0x00 0xd6 0x194 0x3fc 0x00 0x00 0x00 0xd6 0x198 0x400 0x00 0x00 0x00 0xd6 0x19c 0x404 0x00 0x00 0x00 0xd6 0x1a0 0x408 0x00 0x00 0x00 0xd6 0x1a4 0x40c 0x00 0x00 0x00 0xd6 0x1a8 0x410 0x00 0x00 0x00 0xd6 >;
				linux,phandle = < 0x41 >;
				phandle = < 0x41 >;
			};

			sai2grp {
				fsl,pins = < 0x1bc 0x424 0x00 0x00 0x00 0xd6 0x1c0 0x428 0x00 0x00 0x00 0xd6 0x1c8 0x430 0x00 0x00 0x00 0xd6 0x1c4 0x42c 0x00 0x00 0x00 0xd6 0x48 0x2b0 0x00 0x00 0x00 0xd6 >;
				linux,phandle = < 0x43 >;
				phandle = < 0x43 >;
			};

			sai5grp {
				fsl,pins = < 0x158 0x3c0 0x52c 0x00 0x00 0xd6 0x144 0x3ac 0x4d0 0x00 0x00 0xd6 0x140 0x3a8 0x4e4 0x00 0x00 0xd6 0x148 0x3b0 0x4d4 0x00 0x00 0xd6 0x14c 0x3b4 0x4d8 0x00 0x00 0xd6 0x150 0x3b8 0x4dc 0x00 0x00 0xd6 0x154 0x3bc 0x4e0 0x00 0x00 0xd6 >;
				linux,phandle = < 0x42 >;
				phandle = < 0x42 >;
			};

			spdif1grp {
				fsl,pins = < 0x1e8 0x450 0x00 0x00 0x00 0xd6 0x1ec 0x454 0x00 0x00 0x00 0xd6 >;
				linux,phandle = < 0x2c >;
				phandle = < 0x2c >;
			};

			wdoggrp {
				fsl,pins = < 0x30 0x298 0x00 0x01 0x00 0xc6 >;
				linux,phandle = < 0x56 >;
				phandle = < 0x56 >;
			};

			dsi_ts_int {
				fsl,pins = < 0x1f8 0x460 0x00 0x05 0x00 0x19 >;
				linux,phandle = < 0x52 >;
				phandle = < 0x52 >;
			};
		};
	};

	iomuxc-gpr@30340000 {
		compatible = "fsl,imx8mq-iomuxc-gpr\0fsl,imx7d-iomuxc-gpr\0syscon";
		reg = < 0x00 0x30340000 0x00 0x10000 >;
		linux,phandle = < 0x13 >;
		phandle = < 0x13 >;
	};

	ocotp-ctrl@30350000 {
		compatible = "fsl,imx8mq-ocotp\0fsl,imx7d-ocotp\0syscon";
		reg = < 0x00 0x30350000 0x00 0x10000 >;
		clocks = < 0x04 0x110 >;
		#address-cells = < 0x01 >;
		#size-cells = < 0x01 >;
	};

	anatop@30360000 {
		compatible = "fsl,imx8mq-anatop\0fsl,imx6q-anatop\0syscon\0simple-bus";
		reg = < 0x00 0x30360000 0x00 0x10000 >;
		interrupts = < 0x00 0x31 0x04 >;
	};

	snvs@30370000 {
		compatible = "fsl,sec-v4.0-mon\0syscon\0simple-mfd";
		reg = < 0x00 0x30370000 0x00 0x10000 >;
		linux,phandle = < 0x23 >;
		phandle = < 0x23 >;

		snvs-rtc-lp {
			compatible = "fsl,sec-v4.0-mon-rtc-lp";
			regmap = < 0x23 >;
			offset = < 0x34 >;
			interrupts = < 0x00 0x13 0x04 0x00 0x14 0x04 >;
		};

		snvs-powerkey {
			compatible = "fsl,sec-v4.0-pwrkey";
			regmap = < 0x23 >;
			interrupts = < 0x00 0x04 0x04 >;
			linux,keycode = < 0x74 >;
			wakeup-source;
		};
	};

	ccm@30380000 {
		compatible = "fsl,imx8mq-ccm";
		reg = < 0x00 0x30380000 0x00 0x10000 >;
		interrupts = < 0x00 0x55 0x04 0x00 0x56 0x04 >;
		#clock-cells = < 0x01 >;
		clocks = < 0x24 0x25 0x26 0x27 0x28 0x29 0x2a >;
		clock-names = "ckil\0osc_25m\0osc_27m\0clk_ext1\0clk_ext2\0clk_ext3\0clk_ext4";
		assigned-clocks = < 0x04 0x19 0x04 0x1e >;
		assigned-clock-rates = < 0x2ee00000 0x2b110000 >;
		linux,phandle = < 0x04 >;
		phandle = < 0x04 >;
	};

	src@30390000 {
		compatible = "fsl,imx8mq-src\0fsl,imx51-src\0syscon";
		reg = < 0x00 0x30390000 0x00 0x10000 >;
		interrupts = < 0x00 0x59 0x04 >;
		#reset-cells = < 0x01 >;
		linux,phandle = < 0x12 >;
		phandle = < 0x12 >;
	};

	gpc@303a0000 {
		compatible = "fsl,imx8mq-gpc\0fsl,imx7d-gpc\0syscon";
		reg = < 0x00 0x303a0000 0x00 0x10000 >;
		interrupt-controller;
		interrupts = < 0x00 0x57 0x04 >;
		#interrupt-cells = < 0x03 >;
		interrupt-parent = < 0x0a >;
		linux,phandle = < 0x01 >;
		phandle = < 0x01 >;
	};

	system-counter@3036a0000 {
		compatible = "nxp,sysctr-timer";
		reg = < 0x00 0x306a0000 0x00 0x10000 0x00 0x306b0000 0x00 0x10000 0x00 0x306c0000 0x00 0x10000 >;
		clock-frequency = < 0x7f2815 >;
		interrupts = < 0x00 0x2f 0x04 0x00 0x30 0x04 >;
	};

	spdif@30810000 {
		compatible = "fsl,imx8mq-spdif\0fsl,imx35-spdif";
		reg = < 0x00 0x30810000 0x00 0x10000 >;
		interrupts = < 0x00 0x06 0x04 >;
		clocks = < 0x04 0xfa 0x04 0x02 0x04 0x86 0x04 0x00 0x04 0x00 0x04 0x00 0x04 0xfa 0x04 0x00 0x04 0x00 0x04 0x00 >;
		clock-names = "core\0rxtx0\0rxtx1\0rxtx2\0rxtx3\0rxtx4\0rxtx5\0rxtx6\0rxtx7\0spba";
		dmas = < 0x2b 0x08 0x12 0x00 0x2b 0x09 0x12 0x00 >;
		dma-names = "rx\0tx";
		status = "okay";
		pinctrl-names = "default";
		pinctrl-0 = < 0x2c >;
		assigned-clocks = < 0x04 0x86 >;
		assigned-clock-parents = < 0x04 0x1b >;
		assigned-clock-rates = < 0x1770000 >;
		linux,phandle = < 0x62 >;
		phandle = < 0x62 >;
	};

	ecspi@30820000 {
		compatible = "fsl,imx8mq-ecspi\0fsl,imx51-ecspi";
		reg = < 0x00 0x30820000 0x00 0x10000 >;
		interrupts = < 0x00 0x1f 0x04 >;
		clocks = < 0x04 0xc1 0x04 0xc1 >;
		clock-names = "ipg\0per";
		status = "disabled";
		#address-cells = < 0x01 >;
		#size-cells = < 0x00 >;
	};

	ecspi@30830000 {
		#address-cells = < 0x01 >;
		#size-cells = < 0x00 >;
		compatible = "fsl,imx8mq-ecspi\0fsl,imx51-ecspi";
		reg = < 0x00 0x30830000 0x00 0x10000 >;
		interrupts = < 0x00 0x20 0x04 >;
		clocks = < 0x04 0xc2 0x04 0xc2 >;
		clock-names = "ipg\0per";
		status = "disabled";
	};

	ecspi@30840000 {
		#address-cells = < 0x01 >;
		#size-cells = < 0x00 >;
		compatible = "fsl,imx8mq-ecspi\0fsl,imx51-ecspi";
		reg = < 0x00 0x30840000 0x00 0x10000 >;
		interrupts = < 0x00 0x21 0x04 >;
		clocks = < 0x04 0xc3 0x04 0xc3 >;
		clock-names = "ipg\0per";
		status = "disabled";
	};

	serial@30860000 {
		compatible = "fsl,imx8mq-uart\0fsl,imx6q-uart\0fsl,imx21-uart";
		reg = < 0x00 0x30860000 0x00 0x10000 >;
		interrupts = < 0x00 0x1a 0x04 >;
		clocks = < 0x04 0xd8 0x04 0xd8 >;
		clock-names = "ipg\0per";
		status = "okay";
		pinctrl-names = "default";
		pinctrl-0 = < 0x2d >;
		assigned-clocks = < 0x04 0x94 >;
		assigned-clock-parents = < 0x04 0x02 >;
	};

	serial@30880000 {
		compatible = "fsl,imx8mq-uart\0fsl,imx6q-uart\0fsl,imx21-uart";
		reg = < 0x00 0x30880000 0x00 0x10000 >;
		interrupts = < 0x00 0x1c 0x04 >;
		clocks = < 0x04 0xda 0x04 0xda >;
		clock-names = "ipg\0per";
		dmas = < 0x2b 0x1a 0x04 0x00 0x2b 0x1b 0x04 0x00 >;
		dma-names = "rx\0tx";
		status = "okay";
		pinctrl-names = "default";
		pinctrl-0 = < 0x2e >;
		assigned-clocks = < 0x04 0x96 >;
		assigned-clock-parents = < 0x04 0x47 >;
		fsl,uart-has-rtscts;
		resets = < 0x2f >;
	};

	serial@30890000 {
		compatible = "fsl,imx8mq-uart\0fsl,imx6q-uart\0fsl,imx21-uart";
		reg = < 0x00 0x30890000 0x00 0x10000 >;
		interrupts = < 0x00 0x1b 0x04 >;
		clocks = < 0x04 0xd9 0x04 0xd9 >;
		clock-names = "ipg\0per";
		dmas = < 0x2b 0x18 0x04 0x00 0x2b 0x19 0x04 0x00 >;
		dma-names = "rx\0tx";
		status = "disabled";
	};

	spdif@308a0000 {
		compatible = "fsl,imx8mq-spdif\0fsl,imx35-spdif";
		reg = < 0x00 0x308a0000 0x00 0x10000 >;
		interrupts = < 0x00 0x0d 0x04 >;
		clocks = < 0x04 0xfa 0x04 0x02 0x04 0x87 0x04 0x00 0x04 0x00 0x04 0x00 0x04 0xfa 0x04 0x00 0x04 0x00 0x04 0x00 >;
		clock-names = "core\0rxtx0\0rxtx1\0rxtx2\0rxtx3\0rxtx4\0rxtx5\0rxtx6\0rxtx7\0spba";
		dmas = < 0x2b 0x10 0x12 0x00 0x2b 0x11 0x12 0x00 >;
		dma-names = "rx\0tx";
		status = "okay";
		assigned-clocks = < 0x04 0x87 >;
		assigned-clock-parents = < 0x04 0x1b >;
		assigned-clock-rates = < 0x1770000 >;
		linux,phandle = < 0x63 >;
		phandle = < 0x63 >;
	};

	serial@30a60000 {
		compatible = "fsl,imx8mq-uart\0fsl,imx6q-uart\0fsl,imx21-uart";
		reg = < 0x00 0x30a60000 0x00 0x10000 >;
		interrupts = < 0x00 0x1d 0x04 >;
		clocks = < 0x04 0xdb 0x04 0xdb >;
		clock-names = "ipg\0per";
		dmas = < 0x2b 0x1c 0x04 0x00 0x2b 0x1d 0x04 0x00 >;
		dma-names = "rx\0tx";
		status = "disabled";
	};

	mu@30aa0000 {
		compatible = "fsl,imx8mq-mu\0fsl,imx6sx-mu";
		reg = < 0x00 0x30aa0000 0x00 0x10000 >;
		interrupts = < 0x00 0x58 0x04 >;
		clocks = < 0x04 0x113 >;
		clock-names = "mu";
		status = "okay";
	};

	phy@381f0040 {
		compatible = "fsl,imx8mq-usb-phy";
		#phy-cells = < 0x01 >;
		reg = < 0x00 0x381f0040 0x00 0x40 >;
		clocks = < 0x04 0xde >;
		clock-names = "usb_phy_root_clk";
		assigned-clocks = < 0x04 0x99 >;
		assigned-clock-parents = < 0x04 0x48 >;
		assigned-clock-rates = < 0x5f5e100 >;
		status = "okay";
		linux,phandle = < 0x30 >;
		phandle = < 0x30 >;
	};

	usb@38100000 {
		compatible = "fsl, imx8mq-dwc3";
		#address-cells = < 0x02 >;
		#size-cells = < 0x02 >;
		ranges;
		clocks = < 0x04 0xdc >;
		clock-names = "usb1_ctrl_root_clk";
		assigned-clocks = < 0x04 0x6e 0x04 0x98 >;
		assigned-clock-parents = < 0x04 0x56 0x04 0x48 >;
		assigned-clock-rates = < 0x1dcd6500 0x5f5e100 >;
		status = "okay";

		dwc3 {
			compatible = "snps,dwc3";
			reg = < 0x00 0x38100000 0x00 0x10000 >;
			interrupts = < 0x00 0x28 0x04 >;
			phys = < 0x30 0x00 0x30 0x01 >;
			phy-names = "usb2-phy\0usb3-phy";
			power-domains = < 0x31 >;
			snps,power-down-scale = < 0x02 >;
			usb3-resume-missing-cas;
			usb3-lpm-capable;
			snps,has-lpm-erratum;
			snps,lpm-nyet-threshold = < 0x0f >;
			status = "okay";
			extcon = < 0x32 >;
			dr_mode = "otg";
			hnp-disable;
			srp-disable;
			adp-disable;
		};
	};

	phy@382f0040 {
		compatible = "fsl,imx8mq-usb-phy";
		#phy-cells = < 0x01 >;
		reg = < 0x00 0x382f0040 0x00 0x40 >;
		clocks = < 0x04 0xdf >;
		clock-names = "usb_phy_root_clk";
		assigned-clocks = < 0x04 0x99 >;
		assigned-clock-parents = < 0x04 0x48 >;
		assigned-clock-rates = < 0x5f5e100 >;
		status = "okay";
		linux,phandle = < 0x33 >;
		phandle = < 0x33 >;
	};

	usb@38200000 {
		compatible = "fsl, imx8mq-dwc3";
		#address-cells = < 0x02 >;
		#size-cells = < 0x02 >;
		ranges;
		clocks = < 0x04 0xdd >;
		clock-names = "usb2_ctrl_root_clk";
		assigned-clocks = < 0x04 0x6e 0x04 0x98 >;
		assigned-clock-parents = < 0x04 0x56 0x04 0x48 >;
		assigned-clock-rates = < 0x1dcd6500 0x5f5e100 >;
		status = "okay";

		dwc3 {
			compatible = "snps,dwc3";
			reg = < 0x00 0x38200000 0x00 0x10000 >;
			interrupts = < 0x00 0x29 0x04 >;
			phys = < 0x33 0x00 0x33 0x01 >;
			phy-names = "usb2-phy\0usb3-phy";
			power-domains = < 0x34 >;
			snps,power-down-scale = < 0x02 >;
			usb3-resume-missing-cas;
			usb3-lpm-capable;
			status = "okay";
			dr_mode = "host";
		};
	};

	usdhc@30b40000 {
		compatible = "fsl,imx8mq-usdhc\0fsl,imx7d-usdhc";
		reg = < 0x00 0x30b40000 0x00 0x10000 >;
		interrupts = < 0x00 0x16 0x04 >;
		clocks = < 0x04 0x00 0x04 0x69 0x04 0xe0 >;
		clock-names = "ipg\0ahb\0per";
		assigned-clocks = < 0x04 0x8d >;
		assigned-clock-rates = < 0x17d78400 >;
		fsl,tuning-start-tap = < 0x14 >;
		fsl,tuning-step = < 0x02 >;
		fsl,strobe-dll-delay-target = < 0x05 >;
		bus-width = < 0x08 >;
		status = "okay";
		pinctrl-names = "default\0state_100mhz\0state_200mhz";
		pinctrl-0 = < 0x35 >;
		pinctrl-1 = < 0x36 >;
		pinctrl-2 = < 0x37 >;
		non-removable;
	};

	usdhc@30b50000 {
		compatible = "fsl,imx8mq-usdhc\0fsl,imx7d-usdhc";
		reg = < 0x00 0x30b50000 0x00 0x10000 >;
		interrupts = < 0x00 0x17 0x04 >;
		clocks = < 0x04 0x00 0x04 0x69 0x04 0xe1 >;
		clock-names = "ipg\0ahb\0per";
		fsl,tuning-start-tap = < 0x14 >;
		fsl,tuning-step = < 0x02 >;
		bus-width = < 0x04 >;
		status = "okay";
		pinctrl-names = "default\0state_100mhz\0state_200mhz";
		pinctrl-0 = < 0x38 0x39 >;
		pinctrl-1 = < 0x3a 0x39 >;
		pinctrl-2 = < 0x3b 0x39 >;
		cd-gpios = < 0x3c 0x0c 0x01 >;
		vmmc-supply = < 0x3d >;
	};

	sai@30010000 {
		compatible = "fsl,imx8mq-sai\0fsl,imx6sx-sai";
		reg = < 0x00 0x30010000 0x00 0x10000 >;
		interrupts = < 0x00 0x5f 0x04 >;
		clocks = < 0x04 0xfc 0x04 0x00 0x04 0xd2 0x04 0x00 0x04 0x00 0x04 0x1b 0x04 0x20 >;
		clock-names = "bus\0mclk0\0mclk1\0mclk2\0mclk3\0pll8k\0pll11k";
		dmas = < 0x3e 0x08 0x1a 0x00 0x3e 0x09 0x1a 0x00 >;
		dma-names = "rx\0tx";
		fsl,dataline = < 0x00 0xff 0xff >;
		status = "okay";
		pinctrl-names = "default\0pcm_b2m\0dsd";
		pinctrl-0 = < 0x3f >;
		pinctrl-1 = < 0x40 >;
		pinctrl-2 = < 0x41 >;
		assigned-clocks = < 0x04 0x80 >;
		assigned-clock-parents = < 0x04 0x1b >;
		assigned-clock-rates = < 0x2ee0000 >;
		fsl,sai-multi-lane;
		fsl,dataline,dsd = < 0x00 0xff 0xff 0x02 0xff 0x11 >;
		linux,phandle = < 0x64 >;
		phandle = < 0x64 >;
	};

	sai@30030000 {
		compatible = "fsl,imx8mq-sai\0fsl,imx6sx-sai";
		reg = < 0x00 0x30030000 0x00 0x10000 >;
		interrupts = < 0x00 0x5a 0x04 >;
		clocks = < 0x04 0x101 0x04 0x00 0x04 0xd7 0x04 0x00 0x04 0x00 >;
		clock-names = "bus\0mclk0\0mclk1\0mclk2\0mclk3";
		dmas = < 0x3e 0x04 0x18 0x00 0x3e 0x05 0x18 0x00 >;
		dma-names = "rx\0tx";
		fsl,shared-interrupt;
		status = "disabled";
	};

	sai@30040000 {
		compatible = "fsl,imx8mq-sai\0fsl,imx6sx-sai";
		reg = < 0x00 0x30040000 0x00 0x10000 >;
		interrupts = < 0x00 0x5a 0x04 >;
		clocks = < 0x04 0x100 0x04 0x00 0x04 0xd6 0x04 0x00 0x04 0x00 0x04 0x1b 0x04 0x20 >;
		clock-names = "bus\0mclk0\0mclk1\0mclk2\0mclk3\0pll8k\0pll11k";
		dmas = < 0x3e 0x02 0x18 0x00 0x3e 0x03 0x18 0x00 >;
		dma-names = "rx\0tx";
		fsl,shared-interrupt;
		fsl,dataline = < 0x00 0x0f 0x0f >;
		status = "okay";
		pinctrl-names = "default";
		pinctrl-0 = < 0x42 >;
		assigned-clocks = < 0x04 0x84 >;
		assigned-clock-parents = < 0x04 0x1b >;
		assigned-clock-rates = < 0x2ee0000 >;
		fsl,sai-asynchronous;
		linux,phandle = < 0x67 >;
		phandle = < 0x67 >;
	};

	sai@30050000 {
		compatible = "fsl,imx8mq-sai\0fsl,imx6sx-sai";
		reg = < 0x00 0x30050000 0x00 0x10000 >;
		interrupts = < 0x00 0x64 0x04 >;
		clocks = < 0x04 0xff 0x04 0x00 0x04 0xd5 0x04 0x00 0x04 0x00 0x04 0x1b 0x04 0x20 >;
		clock-names = "bus\0mclk0\0mclk1\0mclk2\0mclk3\0pll8k\0pll11k";
		dmas = < 0x3e 0x00 0x18 0x00 0x3e 0x01 0x18 0x00 >;
		dma-names = "rx\0tx";
		fsl,dataline = < 0x00 0x00 0x0f >;
		status = "okay";
		assigned-clocks = < 0x04 0x83 >;
		assigned-clock-parents = < 0x04 0x1b >;
		assigned-clock-rates = < 0x1770000 >;
		linux,phandle = < 0x61 >;
		phandle = < 0x61 >;
	};

	sai@308b0000 {
		compatible = "fsl,imx8mq-sai\0fsl,imx6sx-sai";
		reg = < 0x00 0x308b0000 0x00 0x10000 >;
		interrupts = < 0x00 0x60 0x04 >;
		clocks = < 0x04 0xfd 0x04 0x00 0x04 0xd3 0x04 0x00 0x04 0x00 >;
		clock-names = "bus\0mclk0\0mclk1\0mclk2\0mclk3";
		dmas = < 0x2b 0x0a 0x18 0x00 0x2b 0x0b 0x18 0x00 >;
		dma-names = "rx\0tx";
		status = "okay";
		pinctrl-names = "default";
		pinctrl-0 = < 0x43 >;
		assigned-clocks = < 0x04 0x81 >;
		assigned-clock-parents = < 0x04 0x1b >;
		assigned-clock-rates = < 0x1770000 >;
		linux,phandle = < 0x5f >;
		phandle = < 0x5f >;
	};

	sai@308c0000 {
		compatible = "fsl,imx8mq-sai\0fsl,imx6sx-sai";
		reg = < 0x00 0x308c0000 0x00 0x10000 >;
		interrupts = < 0x00 0x32 0x04 >;
		clocks = < 0x04 0xfe 0x04 0x00 0x04 0xd4 0x04 0x00 0x04 0x00 >;
		clock-names = "bus\0mclk0\0mclk1\0mclk2\0mclk3";
		dmas = < 0x2b 0x0c 0x18 0x00 0x2b 0x0d 0x18 0x00 >;
		dma-names = "rx\0tx";
		status = "disabled";
	};

	sdma@30bd0000 {
		compatible = "fsl,imx8mq-sdma\0fsl,imx7d-sdma";
		reg = < 0x00 0x30bd0000 0x00 0x10000 >;
		interrupts = < 0x00 0x02 0x04 >;
		clocks = < 0x04 0xf1 0x04 0xf1 >;
		clock-names = "ipg\0ahb";
		#dma-cells = < 0x03 >;
		fsl,sdma-ram-script-name = "imx/sdma/sdma-imx7d.bin";
		status = "okay";
		linux,phandle = < 0x2b >;
		phandle = < 0x2b >;
	};

	sdma@302c0000 {
		compatible = "fsl,imx8mq-sdma\0fsl,imx7d-sdma";
		reg = < 0x00 0x302c0000 0x00 0x10000 >;
		interrupts = < 0x00 0x67 0x04 >;
		clocks = < 0x04 0xf2 0x04 0xf2 >;
		clock-names = "ipg\0ahb";
		#dma-cells = < 0x03 >;
		fsl,sdma-ram-script-name = "imx/sdma/sdma-imx7d.bin";
		fsl,ratio-1-1;
		status = "okay";
		linux,phandle = < 0x3e >;
		phandle = < 0x3e >;
	};

	ethernet@30be0000 {
		compatible = "fsl,imx8mq-fec\0fsl,imx6sx-fec";
		reg = < 0x00 0x30be0000 0x00 0x10000 >;
		interrupts = < 0x00 0x76 0x04 0x00 0x77 0x04 0x00 0x78 0x04 >;
		clocks = < 0x04 0xc4 0x04 0xc4 0x04 0x89 0x04 0x88 0x04 0x8a >;
		clock-names = "ipg\0ahb\0ptp\0enet_clk_ref\0enet_out";
		assigned-clocks = < 0x04 0x68 0x04 0x89 0x04 0x88 0x04 0x89 >;
		assigned-clock-parents = < 0x04 0x4c 0x04 0x50 0x04 0x51 >;
		assigned-clock-rates = < 0x00 0x00 0x7735940 0x5f5e100 >;
		stop-mode = < 0x13 0x10 0x03 >;
		fsl,num-tx-queues = < 0x03 >;
		fsl,num-rx-queues = < 0x03 >;
		fsl,wakeup_irq = < 0x02 >;
		status = "okay";
		pinctrl-names = "default";
		pinctrl-0 = < 0x44 >;
		phy-mode = "rgmii-id";
		phy-handle = < 0x45 >;
		fsl,magic-packet;

		mdio {
			#address-cells = < 0x01 >;
			#size-cells = < 0x00 >;

			ethernet-phy@0 {
				compatible = "ethernet-phy-ieee802.3-c22";
				reg = < 0x00 >;
				at803x,led-act-blind-workaround;
				at803x,eee-disabled;
				linux,phandle = < 0x45 >;
				phandle = < 0x45 >;
			};
		};
	};

	gpu@38000000 {
		compatible = "fsl,imx8mq-gpu\0fsl,imx6q-gpu";
		reg = < 0x00 0x38000000 0x00 0x40000 0x00 0x40000000 0x00 0xc0000000 0x00 0x00 0x00 0x10000000 >;
		reg-names = "iobase_3d\0phys_baseaddr\0contiguous_mem";
		interrupts = < 0x00 0x03 0x04 >;
		interrupt-names = "irq_3d";
		clocks = < 0x04 0xe5 0x04 0x66 0x04 0x6f 0x04 0x70 >;
		clock-names = "gpu3d_clk\0gpu3d_shader_clk\0gpu3d_axi_clk\0gpu3d_ahb_clk";
		assigned-clocks = < 0x04 0x61 0x04 0x64 0x04 0x6f 0x04 0x70 >;
		assigned-clock-parents = < 0x04 0x11 0x04 0x11 0x04 0x11 0x04 0x11 >;
		assigned-clock-rates = < 0x2faf0800 0x2faf0800 0x2faf0800 0x2faf0800 >;
		power-domains = < 0x46 >;
		depth-compression = < 0x00 >;
		status = "okay";
	};

	imx_ion {
		compatible = "fsl,mxc-ion";
		fsl,heap-id = < 0x00 >;
	};

	i2c@30a20000 {
		#address-cells = < 0x01 >;
		#size-cells = < 0x00 >;
		compatible = "fsl,imx21-i2c";
		reg = < 0x00 0x30a20000 0x00 0x10000 >;
		interrupts = < 0x00 0x23 0x04 >;
		clocks = < 0x04 0xc6 >;
		status = "okay";
		clock-frequency = < 0x61a80 >;
		pinctrl-names = "default";
		pinctrl-0 = < 0x47 >;

		pfuze100@08 {
			compatible = "fsl,pfuze100";
			reg = < 0x08 >;

			regulators {

				sw1ab {
					regulator-min-microvolt = < 0x493e0 >;
					regulator-max-microvolt = < 0x1c9c38 >;
					linux,phandle = < 0x0b >;
					phandle = < 0x0b >;
				};

				sw1c {
					regulator-min-microvolt = < 0x493e0 >;
					regulator-max-microvolt = < 0x1c9c38 >;
					linux,phandle = < 0x0c >;
					phandle = < 0x0c >;
				};

				sw2 {
					regulator-min-microvolt = < 0xc3500 >;
					regulator-max-microvolt = < 0x325aa0 >;
					regulator-always-on;
				};

				sw3ab {
					regulator-min-microvolt = < 0x61a80 >;
					regulator-max-microvolt = < 0x1e22d8 >;
					regulator-always-on;
				};

				sw4 {
					regulator-min-microvolt = < 0xc3500 >;
					regulator-max-microvolt = < 0x325aa0 >;
					regulator-always-on;
				};

				swbst {
					regulator-min-microvolt = < 0x4c4b40 >;
					regulator-max-microvolt = < 0x4e9530 >;
				};

				vsnvs {
					regulator-min-microvolt = < 0xf4240 >;
					regulator-max-microvolt = < 0x2dc6c0 >;
					regulator-always-on;
				};

				vrefddr {
					regulator-always-on;
				};

				vgen1 {
					regulator-min-microvolt = < 0xc3500 >;
					regulator-max-microvolt = < 0x17a6b0 >;
				};

				vgen2 {
					regulator-min-microvolt = < 0xc3500 >;
					regulator-max-microvolt = < 0x17a6b0 >;
					regulator-always-on;
				};

				vgen3 {
					regulator-min-microvolt = < 0x1b7740 >;
					regulator-max-microvolt = < 0x325aa0 >;
					regulator-always-on;
				};

				vgen4 {
					regulator-min-microvolt = < 0x1b7740 >;
					regulator-max-microvolt = < 0x325aa0 >;
					regulator-always-on;
				};

				vgen5 {
					regulator-min-microvolt = < 0x1b7740 >;
					regulator-max-microvolt = < 0x325aa0 >;
					regulator-always-on;
				};

				vgen6 {
					regulator-min-microvolt = < 0x1b7740 >;
					regulator-max-microvolt = < 0x325aa0 >;
				};
			};
		};

		ptn5110@50 {
			compatible = "usb,tcpci";
			pinctrl-names = "default";
			pinctrl-0 = < 0x48 >;
			reg = < 0x50 >;
			interrupt-parent = < 0x49 >;
			interrupts = < 0x03 0x08 >;
			ss-sel-gpios = < 0x49 0x0f 0x00 >;
			src-pdos = < 0x380190c8 >;
			snk-pdos = < 0x380190c8 0x3802d0c8 >;
			max-snk-mv = < 0x2328 >;
			max-snk-ma = < 0x7d0 >;
			op-snk-mw = < 0x2328 >;
			max-snk-mw = < 0x4650 >;
			port-type = "drp";
			default-role = "sink";
			linux,phandle = < 0x32 >;
			phandle = < 0x32 >;
		};

		ov5640_mipi2@3c {
			compatible = "ovti,ov5640_mipi";
			reg = < 0x3c >;
			status = "okay";
			pinctrl-names = "default";
			pinctrl-0 = < 0x4a 0x4b >;
			clocks = < 0x04 0x115 >;
			clock-names = "csi_mclk";
			assigned-clocks = < 0x04 0x115 >;
			assigned-clock-parents = < 0x04 0x53 >;
			assigned-clock-rates = < 0x1312d00 >;
			csi_id = < 0x01 >;
			pwn-gpios = < 0x4c 0x05 0x00 >;
			mclk = < 0x1312d00 >;
			mclk_source = < 0x00 >;

			port {

				endpoint {
					remote-endpoint = < 0x4d >;
					linux,phandle = < 0x17 >;
					phandle = < 0x17 >;
				};
			};
		};
	};

	i2c@30a30000 {
		#address-cells = < 0x01 >;
		#size-cells = < 0x00 >;
		compatible = "fsl,imx21-i2c";
		reg = < 0x00 0x30a30000 0x00 0x10000 >;
		interrupts = < 0x00 0x24 0x04 >;
		clocks = < 0x04 0xc7 >;
		status = "okay";
		clock-frequency = < 0x186a0 >;
		pinctrl-names = "default";
		pinctrl-0 = < 0x4e >;

		ov5640_mipi@3c {
			compatible = "ovti,ov5640_mipi";
			reg = < 0x3c >;
			status = "okay";
			pinctrl-names = "default";
			pinctrl-0 = < 0x4f >;
			clocks = < 0x04 0x115 >;
			clock-names = "csi_mclk";
			assigned-clocks = < 0x04 0x115 >;
			assigned-clock-parents = < 0x04 0x53 >;
			assigned-clock-rates = < 0x1312d00 >;
			csi_id = < 0x00 >;
			pwn-gpios = < 0x4c 0x03 0x00 >;
			mclk = < 0x1312d00 >;
			mclk_source = < 0x00 >;

			port {

				endpoint {
					remote-endpoint = < 0x50 >;
					linux,phandle = < 0x14 >;
					phandle = < 0x14 >;
				};
			};
		};
	};

	i2c@30a40000 {
		#address-cells = < 0x01 >;
		#size-cells = < 0x00 >;
		compatible = "fsl,imx21-i2c";
		reg = < 0x00 0x30a40000 0x00 0x10000 >;
		interrupts = < 0x00 0x25 0x04 >;
		clocks = < 0x04 0xc8 >;
		status = "okay";
		clock-frequency = < 0x186a0 >;
		pinctrl-names = "default";
		pinctrl-0 = < 0x51 >;

		ak4458@10 {
			compatible = "asahi-kasei,ak4458";
			reg = < 0x10 >;
			linux,phandle = < 0x65 >;
			phandle = < 0x65 >;
		};

		ak4458@12 {
			compatible = "asahi-kasei,ak4458";
			reg = < 0x12 >;
			linux,phandle = < 0x66 >;
			phandle = < 0x66 >;
		};

		ak5558@13 {
			compatible = "asahi-kasei,ak5558";
			reg = < 0x13 >;
			ak5558,pdn-gpio = < 0x49 0x11 0x00 >;
			linux,phandle = < 0x68 >;
			phandle = < 0x68 >;
		};

		ak4497@11 {
			compatible = "asahi-kasei,ak4497";
			reg = < 0x11 >;
			ak4497,pdn-gpio = < 0x49 0x10 0x00 >;
			linux,phandle = < 0x69 >;
			phandle = < 0x69 >;
		};

		synaptics_dsx_ts@20 {
			compatible = "synaptics_dsx";
			reg = < 0x20 >;
			pinctrl-names = "default";
			pinctrl-0 = < 0x52 >;
			interrupt-parent = < 0x53 >;
			interrupts = < 0x07 0x08 >;
			synaptics,diagonal-rotation;
			status = "disabled";
		};

		adv7535@3d {
			compatible = "adi,adv7533";
			reg = < 0x3d >;
			adi,addr-cec = < 0x3b >;
			adi,dsi-lanes = < 0x04 >;
			pinctrl-0 = < 0x52 >;
			interrupt-parent = < 0x53 >;
			interrupts = < 0x07 0x08 >;
			status = "disabled";

			port {

				endpoint {
					remote-endpoint = < 0x54 >;
					linux,phandle = < 0x1f >;
					phandle = < 0x1f >;
				};
			};
		};
	};

	i2c@30a50000 {
		#address-cells = < 0x01 >;
		#size-cells = < 0x00 >;
		compatible = "fsl,imx21-i2c";
		reg = < 0x00 0x30a50000 0x00 0x10000 >;
		interrupts = < 0x00 0x26 0x04 >;
		clocks = < 0x04 0xc9 >;
		status = "disabled";
	};

	vpu@38300000 {
		compatible = "nxp,imx8mq-hantro";
		reg = < 0x00 0x38300000 0x00 0x200000 >;
		reg-names = "regs_hantro";
		interrupts = < 0x00 0x07 0x04 0x00 0x08 0x04 >;
		interrupt-names = "irq_hantro_g1\0irq_hantro_g2";
		clocks = < 0x04 0xf3 0x04 0xf4 0x04 0xed >;
		clock-names = "clk_hantro_g1\0clk_hantro_g2\0clk_hantro_bus";
		assigned-clocks = < 0x04 0x77 0x04 0x78 0x04 0x6a >;
		assigned-clock-parents = < 0x04 0x16 0x04 0x16 0x04 0x4e >;
		assigned-clock-rates = < 0x23c34600 0x23c34600 0x2faf0800 >;
		power-domains = < 0x55 >;
		regulator-supply = < 0x0c >;
		status = "okay";
	};

	wdog@30280000 {
		compatible = "fsl,imx21-wdt";
		reg = < 0x00 0x30280000 0x00 0x10000 >;
		interrupts = < 0x00 0x4e 0x04 >;
		clocks = < 0x04 0xe2 >;
		status = "okay";
		pinctrl-names = "default";
		pinctrl-0 = < 0x56 >;
		fsl,ext-reset-output;
	};

	wdog@30290000 {
		compatible = "fsl,imx21-wdt";
		reg = < 0x00 0x30290000 0x00 0x10000 >;
		interrupts = < 0x00 0x4f 0x04 >;
		clocks = < 0x04 0xe3 >;
		status = "disabled";
	};

	wdog@302a0000 {
		compatible = "fsl,imx21-wdt";
		reg = < 0x00 0x302a0000 0x00 0x10000 >;
		interrupts = < 0x00 0x0a 0x04 >;
		clocks = < 0x04 0xe4 >;
		status = "disabled";
	};

	dma_cap {
		compatible = "dma-capability";
		only-dma-mask32 = < 0x01 >;
	};

	qspi@30bb0000 {
		#address-cells = < 0x01 >;
		#size-cells = < 0x00 >;
		compatible = "fsl,imx7d-qspi";
		reg = < 0x00 0x30bb0000 0x00 0x10000 0x00 0x8000000 0x00 0x10000000 >;
		reg-names = "QuadSPI\0QuadSPI-memory";
		interrupts = < 0x00 0x6b 0x04 >;
		clocks = < 0x04 0xd1 0x04 0xd1 >;
		clock-names = "qspi_en\0qspi";
		status = "okay";
		pinctrl-names = "default";
		pinctrl-0 = < 0x57 >;

		n25q256a@0 {
			reg = < 0x00 >;
			#address-cells = < 0x01 >;
			#size-cells = < 0x01 >;
			compatible = "micron,n25q256a";
			spi-max-frequency = < 0x1ba8140 >;
			spi-nor,ddr-quad-read-dummy = < 0x06 >;
		};
	};

	pcie@0x33800000 {
		compatible = "fsl,imx8mq-pcie\0snps,dw-pcie";
		reg = < 0x00 0x33800000 0x00 0x400000 0x00 0x1ff00000 0x00 0x80000 >;
		reg-names = "dbi\0config";
		reserved-region = < 0x58 >;
		#address-cells = < 0x03 >;
		#size-cells = < 0x02 >;
		device_type = "pci";
		ranges = < 0x81000000 0x00 0x00 0x00 0x1ff80000 0x00 0x10000 0x82000000 0x00 0x18000000 0x00 0x18000000 0x00 0x7f00000 >;
		num-lanes = < 0x01 >;
		interrupts = < 0x00 0x7a 0x04 0x00 0x7f 0x04 >;
		interrupt-names = "msi";
		#interrupt-cells = < 0x01 >;
		interrupt-map-mask = < 0x00 0x00 0x00 0x07 >;
		interrupt-map = < 0x00 0x00 0x00 0x01 0x0a 0x00 0x7d 0x04 0x00 0x00 0x00 0x02 0x0a 0x00 0x7c 0x04 0x00 0x00 0x00 0x03 0x0a 0x00 0x7b 0x04 0x00 0x00 0x00 0x04 0x0a 0x00 0x7a 0x04 >;
		clocks = < 0x04 0xcb 0x04 0x7d 0x04 0x7c >;
		clock-names = "pcie\0pcie_bus\0pcie_phy";
		fsl,max-link-speed = < 0x02 >;
		ctrl-id = < 0x00 >;
		power-domains = < 0x59 >;
		status = "okay";
		pinctrl-names = "default";
		pinctrl-0 = < 0x5a >;
		disable-gpio = < 0x53 0x1d 0x01 >;
		reset-gpio = < 0x53 0x1c 0x01 >;
		ext_osc = < 0x01 >;
		hard-wired = < 0x01 >;
	};

	pcie@0x33c00000 {
		compatible = "fsl,imx8mq-pcie\0snps,dw-pcie";
		reg = < 0x00 0x33c00000 0x00 0x400000 0x00 0x27f00000 0x00 0x80000 >;
		reg-names = "dbi\0config";
		reserved-region = < 0x58 >;
		#address-cells = < 0x03 >;
		#size-cells = < 0x02 >;
		device_type = "pci";
		ranges = < 0x81000000 0x00 0x00 0x00 0x27f80000 0x00 0x10000 0x82000000 0x00 0x20000000 0x00 0x20000000 0x00 0x7f00000 >;
		num-lanes = < 0x01 >;
		interrupts = < 0x00 0x4a 0x04 0x00 0x50 0x04 >;
		interrupt-names = "msi";
		#interrupt-cells = < 0x01 >;
		interrupt-map-mask = < 0x00 0x00 0x00 0x07 >;
		interrupt-map = < 0x00 0x00 0x00 0x01 0x0a 0x00 0x4d 0x04 0x00 0x00 0x00 0x02 0x0a 0x00 0x4c 0x04 0x00 0x00 0x00 0x03 0x0a 0x00 0x4b 0x04 0x00 0x00 0x00 0x04 0x0a 0x00 0x4a 0x04 >;
		clocks = < 0x04 0xcc 0x04 0xaf 0x04 0xae >;
		clock-names = "pcie\0pcie_bus\0pcie_phy";
		fsl,max-link-speed = < 0x02 >;
		ctrl-id = < 0x01 >;
		power-domains = < 0x5b >;
		status = "okay";
		pinctrl-names = "default";
		pinctrl-0 = < 0x5c >;
		disable-gpio = < 0x53 0x0a 0x01 >;
		reset-gpio = < 0x53 0x0c 0x01 >;
		ext_osc = < 0x01 >;
	};

	ddr_pmu@3d800000 {
		compatible = "fsl,imx8-ddr-pmu";
		reg = < 0x00 0x3d800000 0x00 0x400000 >;
		interrupts = < 0x00 0x62 0x04 >;
	};

	imx_rpmsg {
		compatible = "fsl,rpmsg-bus\0simple-bus";
		#address-cells = < 0x02 >;
		#size-cells = < 0x02 >;
		ranges;

		rpmsg {
			compatible = "fsl,imx8qm-rpmsg";
			status = "okay";
			vdev-nums = < 0x01 >;
			reg = < 0x00 0xb8000000 0x00 0x10000 >;
		};
	};

	caam@30900000 {
		compatible = "fsl,sec-v4.0";
		#address-cells = < 0x01 >;
		#size-cells = < 0x01 >;
		reg = < 0x00 0x30900000 0x00 0x40000 >;
		ranges = < 0x00 0x00 0x30900000 0x40000 >;
		interrupts = < 0x00 0x5b 0x04 >;

		jr0@1000 {
			compatible = "fsl,sec-v4.0-job-ring";
			reg = < 0x1000 0x1000 >;
			interrupts = < 0x00 0x69 0x04 >;
		};

		jr1@2000 {
			compatible = "fsl,sec-v4.0-job-ring";
			reg = < 0x2000 0x1000 >;
			interrupts = < 0x00 0x6a 0x04 >;
		};

		jr2@3000 {
			compatible = "fsl,sec-v4.0-job-ring";
			reg = < 0x3000 0x1000 >;
			interrupts = < 0x00 0x72 0x04 >;
		};
	};

	caam-sm@00100000 {
		compatible = "fsl,imx6q-caam-sm";
		reg = < 0x00 0x100000 0x00 0x8000 >;
	};

	caam-snvs@30370000 {
		compatible = "fsl,imx6q-caam-snvs";
		reg = < 0x00 0x30370000 0x00 0x10000 >;
	};

	caam_secvio {
		compatible = "fsl,imx7d-caam-secvio\0fsl,imx6q-caam-secvio";
		interrupts = < 0x00 0x14 0x04 >;
		jtag-tamper = "disabled";
		watchdog-tamper = "enabled";
		internal-boot-tamper = "enabled";
		external-pin-tamper = "disabled";
	};

	dma-apbh@33000000 {
		compatible = "fsl,imx7d-dma-apbh\0fsl,imx28-dma-apbh";
		reg = < 0x00 0x33000000 0x00 0x2000 >;
		interrupts = < 0x00 0x0c 0x04 0x00 0x0c 0x04 0x00 0x0c 0x04 0x00 0x0c 0x04 >;
		interrupt-names = "gpmi0\0gpmi1\0gpmi2\0gpmi3";
		#dma-cells = < 0x01 >;
		dma-channels = < 0x04 >;
		clocks = < 0x04 0x116 >;
		linux,phandle = < 0x5d >;
		phandle = < 0x5d >;
	};

	gpmi-nand@33002000 {
		compatible = "fsl,imx7d-gpmi-nand";
		#address-cells = < 0x01 >;
		#size-cells = < 0x01 >;
		reg = < 0x00 0x33002000 0x00 0x2000 0x00 0x33004000 0x00 0x4000 >;
		reg-names = "gpmi-nand\0bch";
		interrupts = < 0x00 0x0e 0x04 >;
		interrupt-names = "bch";
		clocks = < 0x04 0xf0 0x04 0x116 >;
		clock-names = "gpmi_io\0gpmi_bch_apb";
		dmas = < 0x5d 0x00 >;
		dma-names = "rx-tx";
		status = "disabled";
	};

	chosen {
		bootargs = "console=ttymxc0,115200 earlycon=ec_imx6q,0x30860000,115200";
		stdout-path = "/serial@30860000";
	};

	regulators {
		compatible = "simple-bus";
		#address-cells = < 0x01 >;
		#size-cells = < 0x00 >;

		usdhc2_vmmc {
			compatible = "regulator-fixed";
			regulator-name = "VSD_3V3";
			regulator-min-microvolt = < 0x325aa0 >;
			regulator-max-microvolt = < 0x325aa0 >;
			gpio = < 0x3c 0x13 0x00 >;
			off-on-delay = < 0x4e20 >;
			enable-active-high;
			linux,phandle = < 0x3d >;
			phandle = < 0x3d >;
		};

		regulator-gpio {
			compatible = "regulator-gpio";
			pinctrl-names = "default";
			pinctrl-0 = < 0x5e >;
			regulator-min-microvolt = < 0xdbba0 >;
			regulator-max-microvolt = < 0xf4240 >;
			regulator-name = "gpio_dvfs";
			regulator-type = "voltage";
			gpios = < 0x4c 0x0d 0x00 >;
			states = < 0xdbba0 0x01 0xf4240 0x00 >;
			linux,phandle = < 0x05 >;
			phandle = < 0x05 >;
		};
	};

	modem-reset {
		compatible = "gpio-reset";
		reset-gpios = < 0x49 0x05 0x01 >;
		reset-delay-us = < 0x7d0 >;
		reset-post-delay-ms = < 0x28 >;
		#reset-cells = < 0x00 >;
		linux,phandle = < 0x2f >;
		phandle = < 0x2f >;
	};

	wm8524 {
		compatible = "wlf,wm8524";
		clocks = < 0x04 0xd3 >;
		clock-names = "mclk";
		wlf,mute-gpios = < 0x4c 0x08 0x01 >;
		linux,phandle = < 0x60 >;
		phandle = < 0x60 >;
	};

	sound-wm8524 {
		compatible = "fsl,imx-audio-wm8524";
		model = "wm8524-audio";
		audio-cpu = < 0x5f >;
		audio-codec = < 0x60 >;
		audio-routing = "Line Out Jack\0LINEVOUTL\0Line Out Jack\0LINEVOUTR";
	};

	sound-hdmi {
		compatible = "fsl,imx8mq-evk-cdnhdmi\0fsl,imx-audio-cdnhdmi";
		model = "imx-audio-hdmi";
		audio-cpu = < 0x61 >;
		protocol = < 0x01 >;
		hdmi-out;
		constraint-rate = < 0xac44 0x15888 0x2b110 0x7d00 0xbb80 0x17700 0x2ee00 >;
	};

	sound-spdif {
		compatible = "fsl,imx-audio-spdif";
		model = "imx-spdif";
		spdif-controller = < 0x62 >;
		spdif-out;
		spdif-in;
	};

	sound-hdmi-arc {
		compatible = "fsl,imx-audio-spdif";
		model = "imx-hdmi-arc";
		spdif-controller = < 0x63 >;
		spdif-in;
	};

	sound-ak4458 {
		compatible = "fsl,imx-audio-ak4458-mq";
		model = "ak4458-audio";
		audio-cpu = < 0x64 >;
		audio-codec = < 0x65 0x66 >;
		ak4458,pdn-gpio = < 0x49 0x12 0x00 >;
	};

	sound-ak5558 {
		compatible = "fsl,imx-audio-ak5558-mq";
		model = "ak5558-audio";
		audio-cpu = < 0x67 >;
		audio-codec = < 0x68 >;
	};

	sound-ak4497 {
		compatible = "fsl,imx-audio-ak4497-mq";
		model = "ak4497-audio";
		audio-cpu = < 0x64 >;
		audio-codec = < 0x69 >;
		status = "disabled";
	};
};
